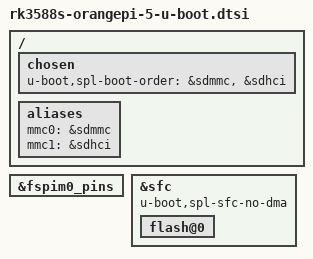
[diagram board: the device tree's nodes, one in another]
// SPDX-License-Identifier: (GPL-2.0+ OR MIT)

#include "rk3588s-u-boot.dtsi"

/ {
	chosen {
		u-boot,spl-boot-order = &sdmmc, &sdhci;
	};
};

/ {
	aliases {
		/* Note: These aliases are for SPL only.
		 * mmc@fe2c0000: 0 (sdmmc/SD)
		 * mmc@fe2e0000: 1 (sdhci/eMMC)
		 */
		mmc0 = &sdmmc; mmc1 = &sdhci;
	};
};

&fspim0_pins {
	bootph-all;
};

&sfc {
	bootph-pre-ram;
	u-boot,spl-sfc-no-dma;

	flash@0 {
		bootph-pre-ram;
	};
};
